# MSP430G2X03 register map
Vendor: msp430gen; File version: v0.4.0-16-g4f822b9
Registers are 8-bit, read-write, reset 0x0 unless marked. A register's access mark holds for its fields unless they carry their own. Offsets are from the block's base; [hi:lo] are bit positions; {n}, {i} and the like mark numbered series.

## SYSTEM_CLOCK
Base 0x00000052
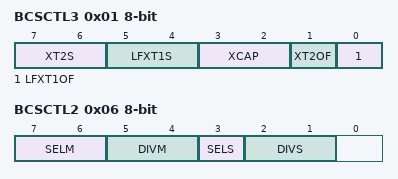
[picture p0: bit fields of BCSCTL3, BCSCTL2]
0x01 BCSCTL3 — Basic Clock System Control 3
  [7:6] XT2S — Mode 0 for XT2
    0=Mode 0 for XT2 : 0.4 - 1 MHz; 1=Mode 1 for XT2 : 1 - 4 MHz; 2=Mode 2 for XT2 : 2 - 16 MHz; 3=Mode 3 for XT2 : Digital input signal
  [5:4] LFXT1S — Mode 0 for LFXT1 (XTS = 0)
    0=Mode 0 for LFXT1 : Normal operation; 1=Mode 1 for LFXT1 : Reserved; 2=Mode 2 for LFXT1 : VLO; 3=Mode 3 for LFXT1 : Digital input signal
  [3:2] XCAP — XIN/XOUT Cap 0
    0=XIN/XOUT Cap : 0 pF; 1=XIN/XOUT Cap : 6 pF; 2=XIN/XOUT Cap : 10 pF; 3=XIN/XOUT Cap : 12.5 pF
  [1] XT2OF — High frequency oscillator 2 fault flag
  [0] LFXT1OF — Low/high Frequency Oscillator Fault Flag
0x04 DCOCTL — DCO Clock Frequency Control
  [7:5] DCO — DCO Select Bit 0
  [7:0] DCOCTL — DCO Clock Frequency Control register
  [4:0] MOD — Modulation Bit 0
0x05 BCSCTL1 — Basic Clock System Control 1
  [7] XT2OFF — Enable XT2CLK
  [6] XTS — LFXTCLK 0:Low Freq. / 1: High Freq.
  [5:4] DIVA — ACLK Divider 0
    0=ACLK Divider 0: /1; 1=ACLK Divider 1: /2; 2=ACLK Divider 2: /4; 3=ACLK Divider 3: /8
  [7:0] BCSCTL1 — Basic Clock System Control 1 register
  [3:0] RSEL — Range Select Bit 0
0x06 BCSCTL2 — Basic Clock System Control 2
  [7:6] SELM — MCLK Source Select 0
    0=MCLK Source Select 0: DCOCLK; 1=MCLK Source Select 1: DCOCLK; 2=MCLK Source Select 2: XT2CLK/LFXTCLK; 3=MCLK Source Select 3: LFXTCLK
  [5:4] DIVM — MCLK Divider 0
    0=MCLK Divider 0: /1; 1=MCLK Divider 1: /2; 2=MCLK Divider 2: /4; 3=MCLK Divider 3: /8
  [3] SELS — SMCLK Source Select 0:DCOCLK / 1:XT2CLK/LFXTCLK
  [2:1] DIVS — SMCLK Divider 0
    0=SMCLK Divider 0: /1; 1=SMCLK Divider 1: /2; 2=SMCLK Divider 2: /4; 3=SMCLK Divider 3: /8

## USCI_A0_UART_MODE
Base 0x0000005C
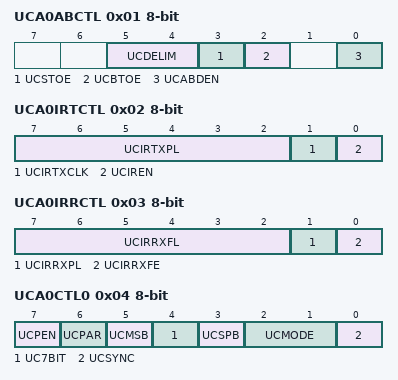
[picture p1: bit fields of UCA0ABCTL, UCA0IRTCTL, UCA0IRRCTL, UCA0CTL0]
0x01 UCA0ABCTL — USCI A0 LIN Control
  [5:4] UCDELIM — Break Sync Delimiter 0
  [3] UCSTOE — Sync-Field Timeout error
  [2] UCBTOE — Break Timeout error
  [0] UCABDEN — Auto Baud Rate detect enable
0x02 UCA0IRTCTL — USCI A0 IrDA Transmit Control
  [7:2] UCIRTXPL — IRDA Transmit Pulse Length 0
  [1] UCIRTXCLK — IRDA Transmit Pulse Clock Select
  [0] UCIREN — IRDA Encoder/Decoder enable
0x03 UCA0IRRCTL — USCI A0 IrDA Receive Control
  [7:2] UCIRRXFL — IRDA Receive Filter Length 0
  [1] UCIRRXPL — IRDA Receive Input Polarity
  [0] UCIRRXFE — IRDA Receive Filter enable
0x04 UCA0CTL0 — USCI A0 Control Register 0
  [7] UCPEN — Async. Mode: Parity enable
  [6] UCPAR — Async. Mode: Parity 0:odd / 1:even
  [5] UCMSB — Async. Mode: MSB first 0:LSB / 1:MSB
  [4] UC7BIT — Async. Mode: Data Bits 0:8-bits / 1:7-bits
  [3] UCSPB — Async. Mode: Stop Bits 0:one / 1: two
  [2:1] UCMODE — Async. Mode: USCI Mode 1
    {v}=Sync. Mode: USCI Mode: {v} (v=0..3)
  [0] UCSYNC — Sync-Mode 0:UART-Mode / 1:SPI-Mode
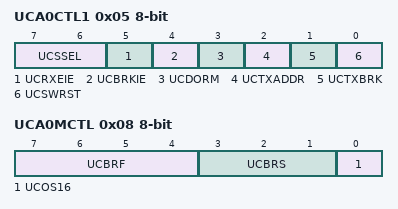
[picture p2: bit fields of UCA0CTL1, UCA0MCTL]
0x05 UCA0CTL1 — USCI A0 Control Register 1
  [7:6] UCSSEL — USCI 0 Clock Source Select 1
    {v}=USCI 0 Clock Source: {v} (v=0..3)
  [5] UCRXEIE — RX Error interrupt enable
  [4] UCBRKIE — Break interrupt enable
  [3] UCDORM — Dormant (Sleep) Mode
  [2] UCTXADDR — Send next Data as Address
  [1] UCTXBRK — Send next Data as Break
  [0] UCSWRST — USCI Software Reset
0x06 UCA0BR0 — USCI A0 Baud Rate 0
  [7:0] UCA0BR0 — USCI A0 Baud Rate 0 register
0x07 UCA0BR1 — USCI A0 Baud Rate 1
  [7:0] UCA0BR1 — USCI A0 Baud Rate 1 register
0x08 UCA0MCTL — USCI A0 Modulation Control
  [7:4] UCBRF — USCI First Stage Modulation Select 3
    {v}=USCI First Stage Modulation: {v} (v=0..9); 10=USCI First Stage Modulation: A; 11=USCI First Stage Modulation: B; 12=USCI First Stage Modulation: C; 13=USCI First Stage Modulation: D; 14=USCI First Stage Modulation: E; 15=USCI First Stage Modulation: F
  [3:1] UCBRS — USCI Second Stage Modulation Select 2
    {v}=USCI Second Stage Modulation: {v} (v=0..7)
  [0] UCOS16 — USCI 16-times Oversampling enable
0x09 UCA0STAT — USCI A0 Status Register
  [7] UCLISTEN — USCI Listen mode
  [6] UCFE — USCI Frame Error Flag
  [5] UCOE — USCI Overrun Error Flag
  [4] UCPE — USCI Parity Error Flag
  [3] UCBRK — USCI Break received
  [2] UCRXERR — USCI RX Error Flag
  [1] UCADDR — USCI Address received Flag
  [1] UCIDLE — Idle line detected
  [0] UCBUSY — USCI Busy Flag
0x0A UCA0RXBUF — USCI A0 Receive Buffer
  [7:0] UCA0RXBUF — USCI A0 Receive Buffer register
0x0B UCA0TXBUF — USCI A0 Transmit Buffer
  [7:0] UCA0TXBUF — USCI A0 Transmit Buffer register
